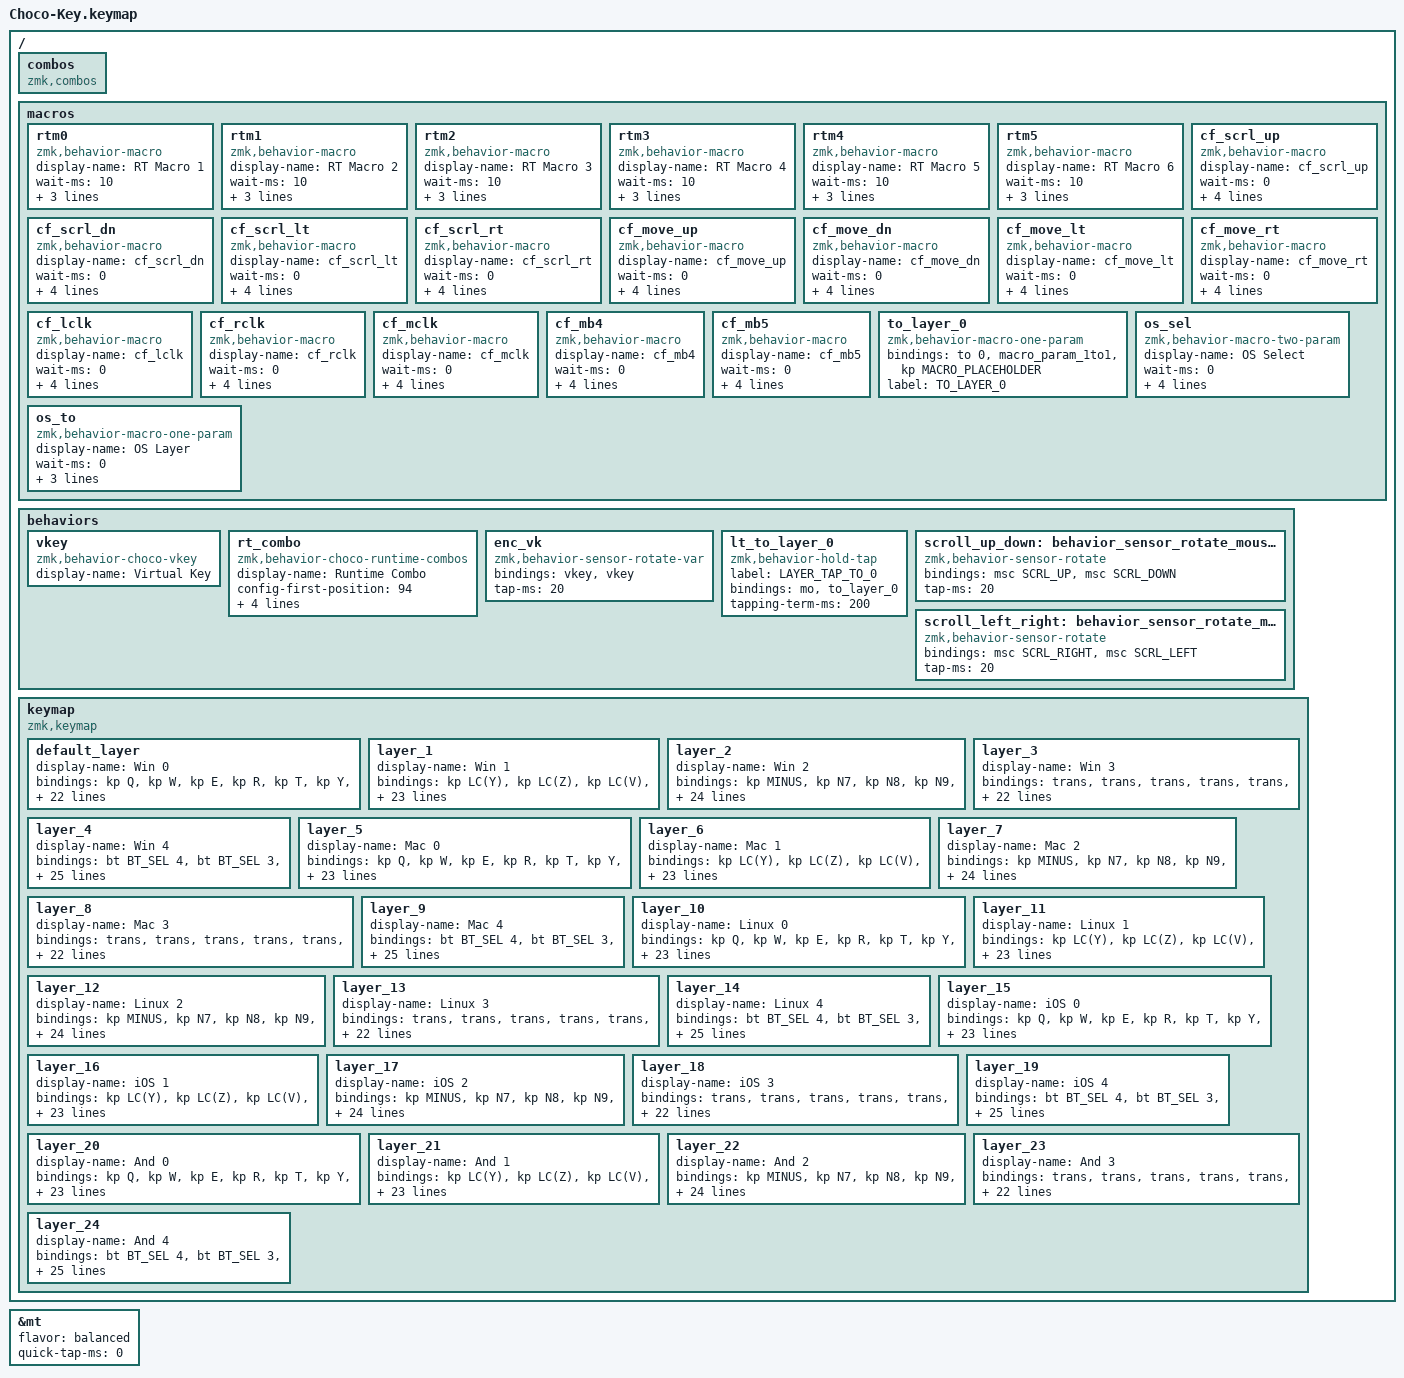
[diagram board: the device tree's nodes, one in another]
/*
 * Choco-Key キーマップ (OS 別 25 レイヤー + 即時編集 / Choco Factory で生成)
 *
 * レイヤー番号 = Bluetooth プロファイル × 5 + レイヤー番号 (プロファイルごとに OS を選べます)
 *   BT 0: 0〜4 / BT 1: 5〜9 / BT 2: 10〜14 / BT 3: 15〜19 / BT 4: 20〜24
 * 各グループの Layer 4 の右手 2 段目に OS 切替キー (&os_sel <BT プロファイル> <レイヤー>) があります。
 * 電源投入時はレイヤー 0 から始まります (ZMK はアクティブなレイヤーを保存しないため)。
 *
 * 各レイヤーのキー 1〜42 は物理キー、43〜126 は物理キーの無い仮想キーです (ZMK Studio で即時に変更できます)。
 *   43〜46: エンコーダー (右 時計回り / 右 反時計回り / 左 時計回り / 左 反時計回り)。レイヤーごとに設定可
 *   47〜94: マクロ &rtm0〜&rtm5 の中身 (8 ステップずつ)。レイヤー 0 で設定し、他のレイヤーは &trans
 *   95〜110: コンボの設定 (&rt_combo)、111〜126: コンボの動作。レイヤー 0 で設定し、他のレイヤーは &trans
 */

#include <behaviors.dtsi>
#include <dt-bindings/zmk/bt.h>
#include <dt-bindings/zmk/keys.h>
#include <dt-bindings/zmk/pointing.h>
#include <behaviors/rgbled_widget.dtsi>

#define ZMK_POINTING_DEFAULT_SCRL_VAL 100

&mt {
    flavor = "balanced";
    quick-tap-ms = <0>;
};

/ {
    combos { compatible = "zmk,combos"; };

    macros {
        // ---- Choco Factory 即時編集マクロ: 中身 (仮想キー 46〜93) は ZMK Studio で変更 ----
        rtm0: rtm0 {
            compatible = "zmk,behavior-macro";
            #binding-cells = <0>;
            display-name = "RT Macro 1";
            wait-ms = <10>;
            tap-ms = <10>;
            bindings = <&vkey 46 &vkey 47 &vkey 48 &vkey 49 &vkey 50 &vkey 51 &vkey 52 &vkey 53>;
        };

        rtm1: rtm1 {
            compatible = "zmk,behavior-macro";
            #binding-cells = <0>;
            display-name = "RT Macro 2";
            wait-ms = <10>;
            tap-ms = <10>;
            bindings = <&vkey 54 &vkey 55 &vkey 56 &vkey 57 &vkey 58 &vkey 59 &vkey 60 &vkey 61>;
        };

        rtm2: rtm2 {
            compatible = "zmk,behavior-macro";
            #binding-cells = <0>;
            display-name = "RT Macro 3";
            wait-ms = <10>;
            tap-ms = <10>;
            bindings = <&vkey 62 &vkey 63 &vkey 64 &vkey 65 &vkey 66 &vkey 67 &vkey 68 &vkey 69>;
        };

        rtm3: rtm3 {
            compatible = "zmk,behavior-macro";
            #binding-cells = <0>;
            display-name = "RT Macro 4";
            wait-ms = <10>;
            tap-ms = <10>;
            bindings = <&vkey 70 &vkey 71 &vkey 72 &vkey 73 &vkey 74 &vkey 75 &vkey 76 &vkey 77>;
        };

        rtm4: rtm4 {
            compatible = "zmk,behavior-macro";
            #binding-cells = <0>;
            display-name = "RT Macro 5";
            wait-ms = <10>;
            tap-ms = <10>;
            bindings = <&vkey 78 &vkey 79 &vkey 80 &vkey 81 &vkey 82 &vkey 83 &vkey 84 &vkey 85>;
        };

        rtm5: rtm5 {
            compatible = "zmk,behavior-macro";
            #binding-cells = <0>;
            display-name = "RT Macro 6";
            wait-ms = <10>;
            tap-ms = <10>;
            bindings = <&vkey 86 &vkey 87 &vkey 88 &vkey 89 &vkey 90 &vkey 91 &vkey 92 &vkey 93>;
        };

        // ---- ZMK Studio から書き込めない &msc / &mmv / &mkp の代わり (ZMK v0.2.1 はこれらのパラメータを検証できないため) ----
        cf_scrl_up: cf_scrl_up {
            compatible = "zmk,behavior-macro";
            #binding-cells = <0>;
            display-name = "cf_scrl_up";
            wait-ms = <0>;
            tap-ms = <0>;
            // 上スクロール: 押している間 &msc SCRL_UP を押し続ける (ZMK Studio から書き込めるようにするため)
            bindings = <&macro_press &msc SCRL_UP>, <&macro_pause_for_release>, <&macro_release &msc SCRL_UP>;
        };

        cf_scrl_dn: cf_scrl_dn {
            compatible = "zmk,behavior-macro";
            #binding-cells = <0>;
            display-name = "cf_scrl_dn";
            wait-ms = <0>;
            tap-ms = <0>;
            // 下スクロール: 押している間 &msc SCRL_DOWN を押し続ける (ZMK Studio から書き込めるようにするため)
            bindings = <&macro_press &msc SCRL_DOWN>, <&macro_pause_for_release>, <&macro_release &msc SCRL_DOWN>;
        };

        cf_scrl_lt: cf_scrl_lt {
            compatible = "zmk,behavior-macro";
            #binding-cells = <0>;
            display-name = "cf_scrl_lt";
            wait-ms = <0>;
            tap-ms = <0>;
            // 左スクロール: 押している間 &msc SCRL_LEFT を押し続ける (ZMK Studio から書き込めるようにするため)
            bindings = <&macro_press &msc SCRL_LEFT>, <&macro_pause_for_release>, <&macro_release &msc SCRL_LEFT>;
        };

        cf_scrl_rt: cf_scrl_rt {
            compatible = "zmk,behavior-macro";
            #binding-cells = <0>;
            display-name = "cf_scrl_rt";
            wait-ms = <0>;
            tap-ms = <0>;
            // 右スクロール: 押している間 &msc SCRL_RIGHT を押し続ける (ZMK Studio から書き込めるようにするため)
            bindings = <&macro_press &msc SCRL_RIGHT>, <&macro_pause_for_release>, <&macro_release &msc SCRL_RIGHT>;
        };

        cf_move_up: cf_move_up {
            compatible = "zmk,behavior-macro";
            #binding-cells = <0>;
            display-name = "cf_move_up";
            wait-ms = <0>;
            tap-ms = <0>;
            // 上へ移動: 押している間 &mmv MOVE_UP を押し続ける (ZMK Studio から書き込めるようにするため)
            bindings = <&macro_press &mmv MOVE_UP>, <&macro_pause_for_release>, <&macro_release &mmv MOVE_UP>;
        };

        cf_move_dn: cf_move_dn {
            compatible = "zmk,behavior-macro";
            #binding-cells = <0>;
            display-name = "cf_move_dn";
            wait-ms = <0>;
            tap-ms = <0>;
            // 下へ移動: 押している間 &mmv MOVE_DOWN を押し続ける (ZMK Studio から書き込めるようにするため)
            bindings = <&macro_press &mmv MOVE_DOWN>, <&macro_pause_for_release>, <&macro_release &mmv MOVE_DOWN>;
        };

        cf_move_lt: cf_move_lt {
            compatible = "zmk,behavior-macro";
            #binding-cells = <0>;
            display-name = "cf_move_lt";
            wait-ms = <0>;
            tap-ms = <0>;
            // 左へ移動: 押している間 &mmv MOVE_LEFT を押し続ける (ZMK Studio から書き込めるようにするため)
            bindings = <&macro_press &mmv MOVE_LEFT>, <&macro_pause_for_release>, <&macro_release &mmv MOVE_LEFT>;
        };

        cf_move_rt: cf_move_rt {
            compatible = "zmk,behavior-macro";
            #binding-cells = <0>;
            display-name = "cf_move_rt";
            wait-ms = <0>;
            tap-ms = <0>;
            // 右へ移動: 押している間 &mmv MOVE_RIGHT を押し続ける (ZMK Studio から書き込めるようにするため)
            bindings = <&macro_press &mmv MOVE_RIGHT>, <&macro_pause_for_release>, <&macro_release &mmv MOVE_RIGHT>;
        };

        cf_lclk: cf_lclk {
            compatible = "zmk,behavior-macro";
            #binding-cells = <0>;
            display-name = "cf_lclk";
            wait-ms = <0>;
            tap-ms = <0>;
            // 左クリック: 押している間 &mkp LCLK を押し続ける (ZMK Studio から書き込めるようにするため)
            bindings = <&macro_press &mkp LCLK>, <&macro_pause_for_release>, <&macro_release &mkp LCLK>;
        };

        cf_rclk: cf_rclk {
            compatible = "zmk,behavior-macro";
            #binding-cells = <0>;
            display-name = "cf_rclk";
            wait-ms = <0>;
            tap-ms = <0>;
            // 右クリック: 押している間 &mkp RCLK を押し続ける (ZMK Studio から書き込めるようにするため)
            bindings = <&macro_press &mkp RCLK>, <&macro_pause_for_release>, <&macro_release &mkp RCLK>;
        };

        cf_mclk: cf_mclk {
            compatible = "zmk,behavior-macro";
            #binding-cells = <0>;
            display-name = "cf_mclk";
            wait-ms = <0>;
            tap-ms = <0>;
            // 中クリック: 押している間 &mkp MCLK を押し続ける (ZMK Studio から書き込めるようにするため)
            bindings = <&macro_press &mkp MCLK>, <&macro_pause_for_release>, <&macro_release &mkp MCLK>;
        };

        cf_mb4: cf_mb4 {
            compatible = "zmk,behavior-macro";
            #binding-cells = <0>;
            display-name = "cf_mb4";
            wait-ms = <0>;
            tap-ms = <0>;
            // 戻る (ボタン4): 押している間 &mkp MB4 を押し続ける (ZMK Studio から書き込めるようにするため)
            bindings = <&macro_press &mkp MB4>, <&macro_pause_for_release>, <&macro_release &mkp MB4>;
        };

        cf_mb5: cf_mb5 {
            compatible = "zmk,behavior-macro";
            #binding-cells = <0>;
            display-name = "cf_mb5";
            wait-ms = <0>;
            tap-ms = <0>;
            // 進む (ボタン5): 押している間 &mkp MB5 を押し続ける (ZMK Studio から書き込めるようにするため)
            bindings = <&macro_press &mkp MB5>, <&macro_pause_for_release>, <&macro_release &mkp MB5>;
        };

        to_layer_0: to_layer_0 {
            compatible = "zmk,behavior-macro-one-param";
            #binding-cells = <1>;
            bindings = <&to 0 &macro_param_1to1 &kp MACRO_PLACEHOLDER>;
            label = "TO_LAYER_0";
        };

        os_sel: os_sel {
            compatible = "zmk,behavior-macro-two-param";
            #binding-cells = <2>;
            display-name = "OS Select";
            wait-ms = <0>;
            tap-ms = <10>;
            // 1 番目のパラメータ = Bluetooth プロファイル、2 番目 = 移動先のレイヤー (&bt の 3 = BT_SEL)
            bindings = <&macro_param_1to2 &bt 3 MACRO_PLACEHOLDER &macro_param_2to1 &to MACRO_PLACEHOLDER>;
        };

        os_to: os_to {
            compatible = "zmk,behavior-macro-one-param";
            #binding-cells = <1>;
            display-name = "OS Layer";
            wait-ms = <0>;
            tap-ms = <10>;
            bindings = <&macro_param_1to1 &to MACRO_PLACEHOLDER>;
        };
    };

    behaviors {
        // ---- Choco Factory 即時編集 (firmware/choco-key/studio/src) ----
        vkey: vkey {
            compatible = "zmk,behavior-choco-vkey";
            #binding-cells = <1>;
            display-name = "Virtual Key";
        };

        rt_combo: rt_combo {
            compatible = "zmk,behavior-choco-runtime-combos";
            #binding-cells = <2>;
            display-name = "Runtime Combo";
            config-first-position = <94>;
            output-first-position = <110>;
            slots = <16>;
            physical-keys = <42>;
            layers-per-group = <5>;
        };

        // エンコーダー: 回すと仮想キー (右 42/43・左 44/45) の割り当てを押す
        enc_vk: enc_vk {
            compatible = "zmk,behavior-sensor-rotate-var";
            #sensor-binding-cells = <2>;
            bindings = <&vkey>, <&vkey>;
            tap-ms = <20>;
        };

        lt_to_layer_0: lt_to_layer_0 {
            compatible = "zmk,behavior-hold-tap";
            label = "LAYER_TAP_TO_0";
            bindings = <&mo>, <&to_layer_0>;

            #binding-cells = <2>;
            tapping-term-ms = <200>;
        };

        scroll_up_down: behavior_sensor_rotate_mouse_wheel_up_down {
            compatible = "zmk,behavior-sensor-rotate";
            #sensor-binding-cells = <0>;
            bindings = <&msc SCRL_UP>, <&msc SCRL_DOWN>;

            tap-ms = <20>;
        };

        scroll_left_right: behavior_sensor_rotate_mouse_wheel_left_right {
            compatible = "zmk,behavior-sensor-rotate";
            #sensor-binding-cells = <0>;
            bindings = <&msc SCRL_RIGHT>, <&msc SCRL_LEFT>;

            tap-ms = <20>;
        };  
    };

    keymap {
        compatible = "zmk,keymap";

        default_layer {
            display-name = "Win 0";
            bindings = <
&kp Q      &kp W           &kp E     &kp R      &kp T                                        &kp Y     &kp U    &kp I           &kp O    &kp P
&kp A      &kp S           &kp D     &kp F      &kp G                                        &kp H     &kp J    &kp K           &kp L    &kp MINUS
&kp Z      &kp X           &kp C     &kp V      &kp B                                        &kp N     &kp M    &kp COMMA       &kp DOT  &kp SLASH
&kp LCTRL  &mt PSCRN LWIN  &kp LALT  &kp LSHFT  &lt 1 LA(GRAVE)  &lt 2 SPACE    &lt 3 ENTER  &kp BSPC  &kp DEL  &mt PSCRN CAPS  &kp TAB  &lt 4 ESC
&msc SCRL_UP  &msc SCRL_DOWN  &msc SCRL_RIGHT  &msc SCRL_LEFT
&none         &none           &none            &none           &none  &none  &none  &none
&none         &none           &none            &none           &none  &none  &none  &none
&none         &none           &none            &none           &none  &none  &none  &none
&none         &none           &none            &none           &none  &none  &none  &none
&none         &none           &none            &none           &none  &none  &none  &none
&none         &none           &none            &none           &none  &none  &none  &none
&none         &none           &none            &none           &none  &none  &none  &none  &none  &none  &none  &none  &none  &none  &none  &none
&none         &none           &none            &none           &none  &none  &none  &none  &none  &none  &none  &none  &none  &none  &none  &none
            >;

            sensor-bindings = <&enc_vk 42 43>, <&enc_vk 44 45>;
        };

        layer_1 {
            display-name = "Win 1";
            bindings = <
&kp LC(Y)  &kp LC(Z)  &kp LC(V)  &kp LC(C)  &kp LC(LS(C))                    &trans  &trans  &trans  &trans  &trans
&trans     &trans     &kp UP     &trans     &kp LC(S)                        &trans  &trans  &trans  &trans  &trans
&trans     &kp LEFT   &kp DOWN   &kp RIGHT  &trans                           &trans  &trans  &trans  &trans  &trans
&trans     &trans     &trans     &trans     &trans         &trans    &trans  &trans  &trans  &trans  &trans  &trans
&msc SCRL_UP  &msc SCRL_DOWN  &msc SCRL_RIGHT  &msc SCRL_LEFT
&trans        &trans          &trans           &trans          &trans  &trans  &trans  &trans
&trans        &trans          &trans           &trans          &trans  &trans  &trans  &trans
&trans        &trans          &trans           &trans          &trans  &trans  &trans  &trans
&trans        &trans          &trans           &trans          &trans  &trans  &trans  &trans
&trans        &trans          &trans           &trans          &trans  &trans  &trans  &trans
&trans        &trans          &trans           &trans          &trans  &trans  &trans  &trans
&trans        &trans          &trans           &trans          &trans  &trans  &trans  &trans  &trans  &trans  &trans  &trans  &trans  &trans  &trans  &trans
&trans        &trans          &trans           &trans          &trans  &trans  &trans  &trans  &trans  &trans  &trans  &trans  &trans  &trans  &trans  &trans
            >;

            sensor-bindings = <&enc_vk 42 43>, <&enc_vk 44 45>;
        };

        layer_2 {
            display-name = "Win 2";
            bindings = <
&kp MINUS  &kp N7  &kp N8  &kp N9  &kp PLUS                     &kp LPAR  &kp RPAR  &kp EXCL  &kp AT     &kp HASH
&kp SLASH  &kp N4  &kp N5  &kp N6  &kp ASTRK                    &kp LBKT  &kp RBKT  &kp DLLR  &kp PRCNT  &kp CARET
&kp N0     &kp N1  &kp N2  &kp N3  &kp EQUAL                    &kp LT    &kp GT    &kp AMPS  &kp SEMI   &kp SQT
&kp CARET  &trans  &trans  &trans  &trans     &trans    &trans  &trans    &trans    &trans    &trans     &trans
&msc SCRL_UP  &msc SCRL_DOWN  &msc SCRL_RIGHT  &msc SCRL_LEFT
&trans        &trans          &trans           &trans          &trans  &trans  &trans  &trans
&trans        &trans          &trans           &trans          &trans  &trans  &trans  &trans
&trans        &trans          &trans           &trans          &trans  &trans  &trans  &trans
&trans        &trans          &trans           &trans          &trans  &trans  &trans  &trans
&trans        &trans          &trans           &trans          &trans  &trans  &trans  &trans
&trans        &trans          &trans           &trans          &trans  &trans  &trans  &trans
&trans        &trans          &trans           &trans          &trans  &trans  &trans  &trans  &trans  &trans  &trans  &trans  &trans  &trans  &trans  &trans
&trans        &trans          &trans           &trans          &trans  &trans  &trans  &trans  &trans  &trans  &trans  &trans  &trans  &trans  &trans  &trans
            >;

            sensor-bindings = <&enc_vk 42 43>, <&enc_vk 44 45>;
        };

        layer_3 {
            display-name = "Win 3";
            bindings = <
&trans  &trans  &trans  &trans  &trans                    &kp F1   &kp F2   &kp F3  &kp F4  &kp F5
&trans  &trans  &trans  &trans  &trans                    &kp F6   &kp F7   &kp F8  &kp F9  &kp F10
&trans  &trans  &trans  &trans  &trans                    &kp F11  &kp F12  &trans  &trans  &trans
&trans  &trans  &trans  &trans  &trans  &trans    &trans  &trans   &trans   &trans  &trans  &trans
&msc SCRL_UP  &msc SCRL_DOWN  &msc SCRL_RIGHT  &msc SCRL_LEFT
&trans        &trans          &trans           &trans          &trans  &trans  &trans  &trans
&trans        &trans          &trans           &trans          &trans  &trans  &trans  &trans
&trans        &trans          &trans           &trans          &trans  &trans  &trans  &trans
&trans        &trans          &trans           &trans          &trans  &trans  &trans  &trans
&trans        &trans          &trans           &trans          &trans  &trans  &trans  &trans
&trans        &trans          &trans           &trans          &trans  &trans  &trans  &trans
&trans        &trans          &trans           &trans          &trans  &trans  &trans  &trans  &trans  &trans  &trans  &trans  &trans  &trans  &trans  &trans
&trans        &trans          &trans           &trans          &trans  &trans  &trans  &trans  &trans  &trans  &trans  &trans  &trans  &trans  &trans  &trans
            >;

            sensor-bindings = <&enc_vk 42 43>, <&enc_vk 44 45>;
        };

        layer_4 {
            display-name = "Win 4";
            bindings = <
&bt BT_SEL 4    &bt BT_SEL 3  &bt BT_SEL 2  &bt BT_SEL 1  &bt BT_SEL 0                         &studio_unlock  &trans       &trans        &trans        &trans
&bt BT_CLR_ALL  &trans        &trans        &trans        &ind_bat                             &os_sel 0 0     &os_sel 1 5  &os_sel 2 10  &os_sel 3 15  &os_sel 4 20
&bt BT_CLR      &trans        &trans        &trans        &trans                               &trans          &trans       &trans        &trans        &trans
&trans          &trans        &trans        &trans        &trans        &bootloader    &trans  &trans          &trans       &trans        &trans        &trans
&msc SCRL_UP  &msc SCRL_DOWN  &msc SCRL_RIGHT  &msc SCRL_LEFT
&trans        &trans          &trans           &trans          &trans  &trans  &trans  &trans
&trans        &trans          &trans           &trans          &trans  &trans  &trans  &trans
&trans        &trans          &trans           &trans          &trans  &trans  &trans  &trans
&trans        &trans          &trans           &trans          &trans  &trans  &trans  &trans
&trans        &trans          &trans           &trans          &trans  &trans  &trans  &trans
&trans        &trans          &trans           &trans          &trans  &trans  &trans  &trans
&trans        &trans          &trans           &trans          &trans  &trans  &trans  &trans  &trans  &trans  &trans  &trans  &trans  &trans  &trans  &trans
&trans        &trans          &trans           &trans          &trans  &trans  &trans  &trans  &trans  &trans  &trans  &trans  &trans  &trans  &trans  &trans
            >;

            sensor-bindings = <&enc_vk 42 43>, <&enc_vk 44 45>;
        };

        layer_5 {
            display-name = "Mac 0";
            bindings = <
&kp Q      &kp W           &kp E     &kp R      &kp T                                        &kp Y     &kp U    &kp I           &kp O    &kp P
&kp A      &kp S           &kp D     &kp F      &kp G                                        &kp H     &kp J    &kp K           &kp L    &kp MINUS
&kp Z      &kp X           &kp C     &kp V      &kp B                                        &kp N     &kp M    &kp COMMA       &kp DOT  &kp SLASH
&kp LCTRL  &mt PSCRN LGUI  &kp LALT  &kp LSHFT  &lt 6 LA(GRAVE)  &lt 7 SPACE    &lt 8 ENTER  &kp BSPC  &kp DEL  &mt PSCRN CAPS  &kp TAB  &lt 9 ESC
&msc SCRL_UP  &msc SCRL_DOWN  &msc SCRL_RIGHT  &msc SCRL_LEFT
&trans        &trans          &trans           &trans          &trans  &trans  &trans  &trans
&trans        &trans          &trans           &trans          &trans  &trans  &trans  &trans
&trans        &trans          &trans           &trans          &trans  &trans  &trans  &trans
&trans        &trans          &trans           &trans          &trans  &trans  &trans  &trans
&trans        &trans          &trans           &trans          &trans  &trans  &trans  &trans
&trans        &trans          &trans           &trans          &trans  &trans  &trans  &trans
&trans        &trans          &trans           &trans          &trans  &trans  &trans  &trans  &trans  &trans  &trans  &trans  &trans  &trans  &trans  &trans
&trans        &trans          &trans           &trans          &trans  &trans  &trans  &trans  &trans  &trans  &trans  &trans  &trans  &trans  &trans  &trans
            >;

            sensor-bindings = <&enc_vk 42 43>, <&enc_vk 44 45>;
        };

        layer_6 {
            display-name = "Mac 1";
            bindings = <
&kp LC(Y)  &kp LC(Z)  &kp LC(V)  &kp LC(C)  &kp LC(LS(C))                    &trans  &trans  &trans  &trans  &trans
&trans     &trans     &kp UP     &trans     &kp LC(S)                        &trans  &trans  &trans  &trans  &trans
&trans     &kp LEFT   &kp DOWN   &kp RIGHT  &trans                           &trans  &trans  &trans  &trans  &trans
&trans     &trans     &trans     &trans     &trans         &trans    &trans  &trans  &trans  &trans  &trans  &trans
&msc SCRL_UP  &msc SCRL_DOWN  &msc SCRL_RIGHT  &msc SCRL_LEFT
&trans        &trans          &trans           &trans          &trans  &trans  &trans  &trans
&trans        &trans          &trans           &trans          &trans  &trans  &trans  &trans
&trans        &trans          &trans           &trans          &trans  &trans  &trans  &trans
&trans        &trans          &trans           &trans          &trans  &trans  &trans  &trans
&trans        &trans          &trans           &trans          &trans  &trans  &trans  &trans
&trans        &trans          &trans           &trans          &trans  &trans  &trans  &trans
&trans        &trans          &trans           &trans          &trans  &trans  &trans  &trans  &trans  &trans  &trans  &trans  &trans  &trans  &trans  &trans
&trans        &trans          &trans           &trans          &trans  &trans  &trans  &trans  &trans  &trans  &trans  &trans  &trans  &trans  &trans  &trans
            >;

            sensor-bindings = <&enc_vk 42 43>, <&enc_vk 44 45>;
        };

        layer_7 {
            display-name = "Mac 2";
            bindings = <
&kp MINUS  &kp N7  &kp N8  &kp N9  &kp PLUS                     &kp LPAR  &kp RPAR  &kp EXCL  &kp AT     &kp HASH
&kp SLASH  &kp N4  &kp N5  &kp N6  &kp ASTRK                    &kp LBKT  &kp RBKT  &kp DLLR  &kp PRCNT  &kp CARET
&kp N0     &kp N1  &kp N2  &kp N3  &kp EQUAL                    &kp LT    &kp GT    &kp AMPS  &kp SEMI   &kp SQT
&kp CARET  &trans  &trans  &trans  &trans     &trans    &trans  &trans    &trans    &trans    &trans     &trans
&msc SCRL_UP  &msc SCRL_DOWN  &msc SCRL_RIGHT  &msc SCRL_LEFT
&trans        &trans          &trans           &trans          &trans  &trans  &trans  &trans
&trans        &trans          &trans           &trans          &trans  &trans  &trans  &trans
&trans        &trans          &trans           &trans          &trans  &trans  &trans  &trans
&trans        &trans          &trans           &trans          &trans  &trans  &trans  &trans
&trans        &trans          &trans           &trans          &trans  &trans  &trans  &trans
&trans        &trans          &trans           &trans          &trans  &trans  &trans  &trans
&trans        &trans          &trans           &trans          &trans  &trans  &trans  &trans  &trans  &trans  &trans  &trans  &trans  &trans  &trans  &trans
&trans        &trans          &trans           &trans          &trans  &trans  &trans  &trans  &trans  &trans  &trans  &trans  &trans  &trans  &trans  &trans
            >;

            sensor-bindings = <&enc_vk 42 43>, <&enc_vk 44 45>;
        };

        layer_8 {
            display-name = "Mac 3";
            bindings = <
&trans  &trans  &trans  &trans  &trans                    &kp F1   &kp F2   &kp F3  &kp F4  &kp F5
&trans  &trans  &trans  &trans  &trans                    &kp F6   &kp F7   &kp F8  &kp F9  &kp F10
&trans  &trans  &trans  &trans  &trans                    &kp F11  &kp F12  &trans  &trans  &trans
&trans  &trans  &trans  &trans  &trans  &trans    &trans  &trans   &trans   &trans  &trans  &trans
&msc SCRL_UP  &msc SCRL_DOWN  &msc SCRL_RIGHT  &msc SCRL_LEFT
&trans        &trans          &trans           &trans          &trans  &trans  &trans  &trans
&trans        &trans          &trans           &trans          &trans  &trans  &trans  &trans
&trans        &trans          &trans           &trans          &trans  &trans  &trans  &trans
&trans        &trans          &trans           &trans          &trans  &trans  &trans  &trans
&trans        &trans          &trans           &trans          &trans  &trans  &trans  &trans
&trans        &trans          &trans           &trans          &trans  &trans  &trans  &trans
&trans        &trans          &trans           &trans          &trans  &trans  &trans  &trans  &trans  &trans  &trans  &trans  &trans  &trans  &trans  &trans
&trans        &trans          &trans           &trans          &trans  &trans  &trans  &trans  &trans  &trans  &trans  &trans  &trans  &trans  &trans  &trans
            >;

            sensor-bindings = <&enc_vk 42 43>, <&enc_vk 44 45>;
        };

        layer_9 {
            display-name = "Mac 4";
            bindings = <
&bt BT_SEL 4    &bt BT_SEL 3  &bt BT_SEL 2  &bt BT_SEL 1  &bt BT_SEL 0                         &studio_unlock  &trans       &trans        &trans        &trans
&bt BT_CLR_ALL  &trans        &trans        &trans        &ind_bat                             &os_sel 0 0     &os_sel 1 5  &os_sel 2 10  &os_sel 3 15  &os_sel 4 20
&bt BT_CLR      &trans        &trans        &trans        &trans                               &trans          &trans       &trans        &trans        &trans
&trans          &trans        &trans        &trans        &trans        &bootloader    &trans  &trans          &trans       &trans        &trans        &trans
&msc SCRL_UP  &msc SCRL_DOWN  &msc SCRL_RIGHT  &msc SCRL_LEFT
&trans        &trans          &trans           &trans          &trans  &trans  &trans  &trans
&trans        &trans          &trans           &trans          &trans  &trans  &trans  &trans
&trans        &trans          &trans           &trans          &trans  &trans  &trans  &trans
&trans        &trans          &trans           &trans          &trans  &trans  &trans  &trans
&trans        &trans          &trans           &trans          &trans  &trans  &trans  &trans
&trans        &trans          &trans           &trans          &trans  &trans  &trans  &trans
&trans        &trans          &trans           &trans          &trans  &trans  &trans  &trans  &trans  &trans  &trans  &trans  &trans  &trans  &trans  &trans
&trans        &trans          &trans           &trans          &trans  &trans  &trans  &trans  &trans  &trans  &trans  &trans  &trans  &trans  &trans  &trans
            >;

            sensor-bindings = <&enc_vk 42 43>, <&enc_vk 44 45>;
        };

        layer_10 {
            display-name = "Linux 0";
            bindings = <
&kp Q      &kp W           &kp E     &kp R      &kp T                                           &kp Y     &kp U    &kp I           &kp O    &kp P
&kp A      &kp S           &kp D     &kp F      &kp G                                           &kp H     &kp J    &kp K           &kp L    &kp MINUS
&kp Z      &kp X           &kp C     &kp V      &kp B                                           &kp N     &kp M    &kp COMMA       &kp DOT  &kp SLASH
&kp LCTRL  &mt PSCRN LGUI  &kp LALT  &kp LSHFT  &lt 11 LA(GRAVE)  &lt 12 SPACE    &lt 13 ENTER  &kp BSPC  &kp DEL  &mt PSCRN CAPS  &kp TAB  &lt 14 ESC
&msc SCRL_UP  &msc SCRL_DOWN  &msc SCRL_RIGHT  &msc SCRL_LEFT
&trans        &trans          &trans           &trans          &trans  &trans  &trans  &trans
&trans        &trans          &trans           &trans          &trans  &trans  &trans  &trans
&trans        &trans          &trans           &trans          &trans  &trans  &trans  &trans
&trans        &trans          &trans           &trans          &trans  &trans  &trans  &trans
&trans        &trans          &trans           &trans          &trans  &trans  &trans  &trans
&trans        &trans          &trans           &trans          &trans  &trans  &trans  &trans
&trans        &trans          &trans           &trans          &trans  &trans  &trans  &trans  &trans  &trans  &trans  &trans  &trans  &trans  &trans  &trans
&trans        &trans          &trans           &trans          &trans  &trans  &trans  &trans  &trans  &trans  &trans  &trans  &trans  &trans  &trans  &trans
            >;

            sensor-bindings = <&enc_vk 42 43>, <&enc_vk 44 45>;
        };

        layer_11 {
            display-name = "Linux 1";
            bindings = <
&kp LC(Y)  &kp LC(Z)  &kp LC(V)  &kp LC(C)  &kp LC(LS(C))                    &trans  &trans  &trans  &trans  &trans
&trans     &trans     &kp UP     &trans     &kp LC(S)                        &trans  &trans  &trans  &trans  &trans
&trans     &kp LEFT   &kp DOWN   &kp RIGHT  &trans                           &trans  &trans  &trans  &trans  &trans
&trans     &trans     &trans     &trans     &trans         &trans    &trans  &trans  &trans  &trans  &trans  &trans
&msc SCRL_UP  &msc SCRL_DOWN  &msc SCRL_RIGHT  &msc SCRL_LEFT
&trans        &trans          &trans           &trans          &trans  &trans  &trans  &trans
&trans        &trans          &trans           &trans          &trans  &trans  &trans  &trans
&trans        &trans          &trans           &trans          &trans  &trans  &trans  &trans
&trans        &trans          &trans           &trans          &trans  &trans  &trans  &trans
&trans        &trans          &trans           &trans          &trans  &trans  &trans  &trans
&trans        &trans          &trans           &trans          &trans  &trans  &trans  &trans
&trans        &trans          &trans           &trans          &trans  &trans  &trans  &trans  &trans  &trans  &trans  &trans  &trans  &trans  &trans  &trans
&trans        &trans          &trans           &trans          &trans  &trans  &trans  &trans  &trans  &trans  &trans  &trans  &trans  &trans  &trans  &trans
            >;

            sensor-bindings = <&enc_vk 42 43>, <&enc_vk 44 45>;
        };

        layer_12 {
            display-name = "Linux 2";
            bindings = <
&kp MINUS  &kp N7  &kp N8  &kp N9  &kp PLUS                     &kp LPAR  &kp RPAR  &kp EXCL  &kp AT     &kp HASH
&kp SLASH  &kp N4  &kp N5  &kp N6  &kp ASTRK                    &kp LBKT  &kp RBKT  &kp DLLR  &kp PRCNT  &kp CARET
&kp N0     &kp N1  &kp N2  &kp N3  &kp EQUAL                    &kp LT    &kp GT    &kp AMPS  &kp SEMI   &kp SQT
&kp CARET  &trans  &trans  &trans  &trans     &trans    &trans  &trans    &trans    &trans    &trans     &trans
&msc SCRL_UP  &msc SCRL_DOWN  &msc SCRL_RIGHT  &msc SCRL_LEFT
&trans        &trans          &trans           &trans          &trans  &trans  &trans  &trans
&trans        &trans          &trans           &trans          &trans  &trans  &trans  &trans
&trans        &trans          &trans           &trans          &trans  &trans  &trans  &trans
&trans        &trans          &trans           &trans          &trans  &trans  &trans  &trans
&trans        &trans          &trans           &trans          &trans  &trans  &trans  &trans
&trans        &trans          &trans           &trans          &trans  &trans  &trans  &trans
&trans        &trans          &trans           &trans          &trans  &trans  &trans  &trans  &trans  &trans  &trans  &trans  &trans  &trans  &trans  &trans
&trans        &trans          &trans           &trans          &trans  &trans  &trans  &trans  &trans  &trans  &trans  &trans  &trans  &trans  &trans  &trans
            >;

            sensor-bindings = <&enc_vk 42 43>, <&enc_vk 44 45>;
        };

        layer_13 {
            display-name = "Linux 3";
            bindings = <
&trans  &trans  &trans  &trans  &trans                    &kp F1   &kp F2   &kp F3  &kp F4  &kp F5
&trans  &trans  &trans  &trans  &trans                    &kp F6   &kp F7   &kp F8  &kp F9  &kp F10
&trans  &trans  &trans  &trans  &trans                    &kp F11  &kp F12  &trans  &trans  &trans
&trans  &trans  &trans  &trans  &trans  &trans    &trans  &trans   &trans   &trans  &trans  &trans
&msc SCRL_UP  &msc SCRL_DOWN  &msc SCRL_RIGHT  &msc SCRL_LEFT
&trans        &trans          &trans           &trans          &trans  &trans  &trans  &trans
&trans        &trans          &trans           &trans          &trans  &trans  &trans  &trans
&trans        &trans          &trans           &trans          &trans  &trans  &trans  &trans
&trans        &trans          &trans           &trans          &trans  &trans  &trans  &trans
&trans        &trans          &trans           &trans          &trans  &trans  &trans  &trans
&trans        &trans          &trans           &trans          &trans  &trans  &trans  &trans
&trans        &trans          &trans           &trans          &trans  &trans  &trans  &trans  &trans  &trans  &trans  &trans  &trans  &trans  &trans  &trans
&trans        &trans          &trans           &trans          &trans  &trans  &trans  &trans  &trans  &trans  &trans  &trans  &trans  &trans  &trans  &trans
            >;

            sensor-bindings = <&enc_vk 42 43>, <&enc_vk 44 45>;
        };

        layer_14 {
            display-name = "Linux 4";
            bindings = <
&bt BT_SEL 4    &bt BT_SEL 3  &bt BT_SEL 2  &bt BT_SEL 1  &bt BT_SEL 0                         &studio_unlock  &trans       &trans        &trans        &trans
&bt BT_CLR_ALL  &trans        &trans        &trans        &ind_bat                             &os_sel 0 0     &os_sel 1 5  &os_sel 2 10  &os_sel 3 15  &os_sel 4 20
&bt BT_CLR      &trans        &trans        &trans        &trans                               &trans          &trans       &trans        &trans        &trans
&trans          &trans        &trans        &trans        &trans        &bootloader    &trans  &trans          &trans       &trans        &trans        &trans
&msc SCRL_UP  &msc SCRL_DOWN  &msc SCRL_RIGHT  &msc SCRL_LEFT
&trans        &trans          &trans           &trans          &trans  &trans  &trans  &trans
&trans        &trans          &trans           &trans          &trans  &trans  &trans  &trans
&trans        &trans          &trans           &trans          &trans  &trans  &trans  &trans
&trans        &trans          &trans           &trans          &trans  &trans  &trans  &trans
&trans        &trans          &trans           &trans          &trans  &trans  &trans  &trans
&trans        &trans          &trans           &trans          &trans  &trans  &trans  &trans
&trans        &trans          &trans           &trans          &trans  &trans  &trans  &trans  &trans  &trans  &trans  &trans  &trans  &trans  &trans  &trans
&trans        &trans          &trans           &trans          &trans  &trans  &trans  &trans  &trans  &trans  &trans  &trans  &trans  &trans  &trans  &trans
            >;

            sensor-bindings = <&enc_vk 42 43>, <&enc_vk 44 45>;
        };

        layer_15 {
            display-name = "iOS 0";
            bindings = <
&kp Q      &kp W           &kp E     &kp R      &kp T                                           &kp Y     &kp U    &kp I           &kp O    &kp P
&kp A      &kp S           &kp D     &kp F      &kp G                                           &kp H     &kp J    &kp K           &kp L    &kp MINUS
&kp Z      &kp X           &kp C     &kp V      &kp B                                           &kp N     &kp M    &kp COMMA       &kp DOT  &kp SLASH
&kp LCTRL  &mt PSCRN LGUI  &kp LALT  &kp LSHFT  &lt 16 LA(GRAVE)  &lt 17 SPACE    &lt 18 ENTER  &kp BSPC  &kp DEL  &mt PSCRN CAPS  &kp TAB  &lt 19 ESC
&msc SCRL_UP  &msc SCRL_DOWN  &msc SCRL_RIGHT  &msc SCRL_LEFT
&trans        &trans          &trans           &trans          &trans  &trans  &trans  &trans
&trans        &trans          &trans           &trans          &trans  &trans  &trans  &trans
&trans        &trans          &trans           &trans          &trans  &trans  &trans  &trans
&trans        &trans          &trans           &trans          &trans  &trans  &trans  &trans
&trans        &trans          &trans           &trans          &trans  &trans  &trans  &trans
&trans        &trans          &trans           &trans          &trans  &trans  &trans  &trans
&trans        &trans          &trans           &trans          &trans  &trans  &trans  &trans  &trans  &trans  &trans  &trans  &trans  &trans  &trans  &trans
&trans        &trans          &trans           &trans          &trans  &trans  &trans  &trans  &trans  &trans  &trans  &trans  &trans  &trans  &trans  &trans
            >;

            sensor-bindings = <&enc_vk 42 43>, <&enc_vk 44 45>;
        };

        layer_16 {
            display-name = "iOS 1";
            bindings = <
&kp LC(Y)  &kp LC(Z)  &kp LC(V)  &kp LC(C)  &kp LC(LS(C))                    &trans  &trans  &trans  &trans  &trans
&trans     &trans     &kp UP     &trans     &kp LC(S)                        &trans  &trans  &trans  &trans  &trans
&trans     &kp LEFT   &kp DOWN   &kp RIGHT  &trans                           &trans  &trans  &trans  &trans  &trans
&trans     &trans     &trans     &trans     &trans         &trans    &trans  &trans  &trans  &trans  &trans  &trans
&msc SCRL_UP  &msc SCRL_DOWN  &msc SCRL_RIGHT  &msc SCRL_LEFT
&trans        &trans          &trans           &trans          &trans  &trans  &trans  &trans
&trans        &trans          &trans           &trans          &trans  &trans  &trans  &trans
&trans        &trans          &trans           &trans          &trans  &trans  &trans  &trans
&trans        &trans          &trans           &trans          &trans  &trans  &trans  &trans
&trans        &trans          &trans           &trans          &trans  &trans  &trans  &trans
&trans        &trans          &trans           &trans          &trans  &trans  &trans  &trans
&trans        &trans          &trans           &trans          &trans  &trans  &trans  &trans  &trans  &trans  &trans  &trans  &trans  &trans  &trans  &trans
&trans        &trans          &trans           &trans          &trans  &trans  &trans  &trans  &trans  &trans  &trans  &trans  &trans  &trans  &trans  &trans
            >;

            sensor-bindings = <&enc_vk 42 43>, <&enc_vk 44 45>;
        };

        layer_17 {
            display-name = "iOS 2";
            bindings = <
&kp MINUS  &kp N7  &kp N8  &kp N9  &kp PLUS                     &kp LPAR  &kp RPAR  &kp EXCL  &kp AT     &kp HASH
&kp SLASH  &kp N4  &kp N5  &kp N6  &kp ASTRK                    &kp LBKT  &kp RBKT  &kp DLLR  &kp PRCNT  &kp CARET
&kp N0     &kp N1  &kp N2  &kp N3  &kp EQUAL                    &kp LT    &kp GT    &kp AMPS  &kp SEMI   &kp SQT
&kp CARET  &trans  &trans  &trans  &trans     &trans    &trans  &trans    &trans    &trans    &trans     &trans
&msc SCRL_UP  &msc SCRL_DOWN  &msc SCRL_RIGHT  &msc SCRL_LEFT
&trans        &trans          &trans           &trans          &trans  &trans  &trans  &trans
&trans        &trans          &trans           &trans          &trans  &trans  &trans  &trans
&trans        &trans          &trans           &trans          &trans  &trans  &trans  &trans
&trans        &trans          &trans           &trans          &trans  &trans  &trans  &trans
&trans        &trans          &trans           &trans          &trans  &trans  &trans  &trans
&trans        &trans          &trans           &trans          &trans  &trans  &trans  &trans
&trans        &trans          &trans           &trans          &trans  &trans  &trans  &trans  &trans  &trans  &trans  &trans  &trans  &trans  &trans  &trans
&trans        &trans          &trans           &trans          &trans  &trans  &trans  &trans  &trans  &trans  &trans  &trans  &trans  &trans  &trans  &trans
            >;

            sensor-bindings = <&enc_vk 42 43>, <&enc_vk 44 45>;
        };

        layer_18 {
            display-name = "iOS 3";
            bindings = <
&trans  &trans  &trans  &trans  &trans                    &kp F1   &kp F2   &kp F3  &kp F4  &kp F5
&trans  &trans  &trans  &trans  &trans                    &kp F6   &kp F7   &kp F8  &kp F9  &kp F10
&trans  &trans  &trans  &trans  &trans                    &kp F11  &kp F12  &trans  &trans  &trans
&trans  &trans  &trans  &trans  &trans  &trans    &trans  &trans   &trans   &trans  &trans  &trans
&msc SCRL_UP  &msc SCRL_DOWN  &msc SCRL_RIGHT  &msc SCRL_LEFT
&trans        &trans          &trans           &trans          &trans  &trans  &trans  &trans
&trans        &trans          &trans           &trans          &trans  &trans  &trans  &trans
&trans        &trans          &trans           &trans          &trans  &trans  &trans  &trans
&trans        &trans          &trans           &trans          &trans  &trans  &trans  &trans
&trans        &trans          &trans           &trans          &trans  &trans  &trans  &trans
&trans        &trans          &trans           &trans          &trans  &trans  &trans  &trans
&trans        &trans          &trans           &trans          &trans  &trans  &trans  &trans  &trans  &trans  &trans  &trans  &trans  &trans  &trans  &trans
&trans        &trans          &trans           &trans          &trans  &trans  &trans  &trans  &trans  &trans  &trans  &trans  &trans  &trans  &trans  &trans
            >;

            sensor-bindings = <&enc_vk 42 43>, <&enc_vk 44 45>;
        };

        layer_19 {
            display-name = "iOS 4";
            bindings = <
&bt BT_SEL 4    &bt BT_SEL 3  &bt BT_SEL 2  &bt BT_SEL 1  &bt BT_SEL 0                         &studio_unlock  &trans       &trans        &trans        &trans
&bt BT_CLR_ALL  &trans        &trans        &trans        &ind_bat                             &os_sel 0 0     &os_sel 1 5  &os_sel 2 10  &os_sel 3 15  &os_sel 4 20
&bt BT_CLR      &trans        &trans        &trans        &trans                               &trans          &trans       &trans        &trans        &trans
&trans          &trans        &trans        &trans        &trans        &bootloader    &trans  &trans          &trans       &trans        &trans        &trans
&msc SCRL_UP  &msc SCRL_DOWN  &msc SCRL_RIGHT  &msc SCRL_LEFT
&trans        &trans          &trans           &trans          &trans  &trans  &trans  &trans
&trans        &trans          &trans           &trans          &trans  &trans  &trans  &trans
&trans        &trans          &trans           &trans          &trans  &trans  &trans  &trans
&trans        &trans          &trans           &trans          &trans  &trans  &trans  &trans
&trans        &trans          &trans           &trans          &trans  &trans  &trans  &trans
&trans        &trans          &trans           &trans          &trans  &trans  &trans  &trans
&trans        &trans          &trans           &trans          &trans  &trans  &trans  &trans  &trans  &trans  &trans  &trans  &trans  &trans  &trans  &trans
&trans        &trans          &trans           &trans          &trans  &trans  &trans  &trans  &trans  &trans  &trans  &trans  &trans  &trans  &trans  &trans
            >;

            sensor-bindings = <&enc_vk 42 43>, <&enc_vk 44 45>;
        };

        layer_20 {
            display-name = "And 0";
            bindings = <
&kp Q      &kp W           &kp E     &kp R      &kp T                                           &kp Y     &kp U    &kp I           &kp O    &kp P
&kp A      &kp S           &kp D     &kp F      &kp G                                           &kp H     &kp J    &kp K           &kp L    &kp MINUS
&kp Z      &kp X           &kp C     &kp V      &kp B                                           &kp N     &kp M    &kp COMMA       &kp DOT  &kp SLASH
&kp LCTRL  &mt PSCRN LGUI  &kp LALT  &kp LSHFT  &lt 21 LA(GRAVE)  &lt 22 SPACE    &lt 23 ENTER  &kp BSPC  &kp DEL  &mt PSCRN CAPS  &kp TAB  &lt 24 ESC
&msc SCRL_UP  &msc SCRL_DOWN  &msc SCRL_RIGHT  &msc SCRL_LEFT
&trans        &trans          &trans           &trans          &trans  &trans  &trans  &trans
&trans        &trans          &trans           &trans          &trans  &trans  &trans  &trans
&trans        &trans          &trans           &trans          &trans  &trans  &trans  &trans
&trans        &trans          &trans           &trans          &trans  &trans  &trans  &trans
&trans        &trans          &trans           &trans          &trans  &trans  &trans  &trans
&trans        &trans          &trans           &trans          &trans  &trans  &trans  &trans
&trans        &trans          &trans           &trans          &trans  &trans  &trans  &trans  &trans  &trans  &trans  &trans  &trans  &trans  &trans  &trans
&trans        &trans          &trans           &trans          &trans  &trans  &trans  &trans  &trans  &trans  &trans  &trans  &trans  &trans  &trans  &trans
            >;

            sensor-bindings = <&enc_vk 42 43>, <&enc_vk 44 45>;
        };

        layer_21 {
            display-name = "And 1";
            bindings = <
&kp LC(Y)  &kp LC(Z)  &kp LC(V)  &kp LC(C)  &kp LC(LS(C))                    &trans  &trans  &trans  &trans  &trans
&trans     &trans     &kp UP     &trans     &kp LC(S)                        &trans  &trans  &trans  &trans  &trans
&trans     &kp LEFT   &kp DOWN   &kp RIGHT  &trans                           &trans  &trans  &trans  &trans  &trans
&trans     &trans     &trans     &trans     &trans         &trans    &trans  &trans  &trans  &trans  &trans  &trans
&msc SCRL_UP  &msc SCRL_DOWN  &msc SCRL_RIGHT  &msc SCRL_LEFT
&trans        &trans          &trans           &trans          &trans  &trans  &trans  &trans
&trans        &trans          &trans           &trans          &trans  &trans  &trans  &trans
&trans        &trans          &trans           &trans          &trans  &trans  &trans  &trans
&trans        &trans          &trans           &trans          &trans  &trans  &trans  &trans
&trans        &trans          &trans           &trans          &trans  &trans  &trans  &trans
&trans        &trans          &trans           &trans          &trans  &trans  &trans  &trans
&trans        &trans          &trans           &trans          &trans  &trans  &trans  &trans  &trans  &trans  &trans  &trans  &trans  &trans  &trans  &trans
&trans        &trans          &trans           &trans          &trans  &trans  &trans  &trans  &trans  &trans  &trans  &trans  &trans  &trans  &trans  &trans
            >;

            sensor-bindings = <&enc_vk 42 43>, <&enc_vk 44 45>;
        };

        layer_22 {
            display-name = "And 2";
            bindings = <
&kp MINUS  &kp N7  &kp N8  &kp N9  &kp PLUS                     &kp LPAR  &kp RPAR  &kp EXCL  &kp AT     &kp HASH
&kp SLASH  &kp N4  &kp N5  &kp N6  &kp ASTRK                    &kp LBKT  &kp RBKT  &kp DLLR  &kp PRCNT  &kp CARET
&kp N0     &kp N1  &kp N2  &kp N3  &kp EQUAL                    &kp LT    &kp GT    &kp AMPS  &kp SEMI   &kp SQT
&kp CARET  &trans  &trans  &trans  &trans     &trans    &trans  &trans    &trans    &trans    &trans     &trans
&msc SCRL_UP  &msc SCRL_DOWN  &msc SCRL_RIGHT  &msc SCRL_LEFT
&trans        &trans          &trans           &trans          &trans  &trans  &trans  &trans
&trans        &trans          &trans           &trans          &trans  &trans  &trans  &trans
&trans        &trans          &trans           &trans          &trans  &trans  &trans  &trans
&trans        &trans          &trans           &trans          &trans  &trans  &trans  &trans
&trans        &trans          &trans           &trans          &trans  &trans  &trans  &trans
&trans        &trans          &trans           &trans          &trans  &trans  &trans  &trans
&trans        &trans          &trans           &trans          &trans  &trans  &trans  &trans  &trans  &trans  &trans  &trans  &trans  &trans  &trans  &trans
&trans        &trans          &trans           &trans          &trans  &trans  &trans  &trans  &trans  &trans  &trans  &trans  &trans  &trans  &trans  &trans
            >;

            sensor-bindings = <&enc_vk 42 43>, <&enc_vk 44 45>;
        };

        layer_23 {
            display-name = "And 3";
            bindings = <
&trans  &trans  &trans  &trans  &trans                    &kp F1   &kp F2   &kp F3  &kp F4  &kp F5
&trans  &trans  &trans  &trans  &trans                    &kp F6   &kp F7   &kp F8  &kp F9  &kp F10
&trans  &trans  &trans  &trans  &trans                    &kp F11  &kp F12  &trans  &trans  &trans
&trans  &trans  &trans  &trans  &trans  &trans    &trans  &trans   &trans   &trans  &trans  &trans
&msc SCRL_UP  &msc SCRL_DOWN  &msc SCRL_RIGHT  &msc SCRL_LEFT
&trans        &trans          &trans           &trans          &trans  &trans  &trans  &trans
&trans        &trans          &trans           &trans          &trans  &trans  &trans  &trans
&trans        &trans          &trans           &trans          &trans  &trans  &trans  &trans
&trans        &trans          &trans           &trans          &trans  &trans  &trans  &trans
&trans        &trans          &trans           &trans          &trans  &trans  &trans  &trans
&trans        &trans          &trans           &trans          &trans  &trans  &trans  &trans
&trans        &trans          &trans           &trans          &trans  &trans  &trans  &trans  &trans  &trans  &trans  &trans  &trans  &trans  &trans  &trans
&trans        &trans          &trans           &trans          &trans  &trans  &trans  &trans  &trans  &trans  &trans  &trans  &trans  &trans  &trans  &trans
            >;

            sensor-bindings = <&enc_vk 42 43>, <&enc_vk 44 45>;
        };

        layer_24 {
            display-name = "And 4";
            bindings = <
&bt BT_SEL 4    &bt BT_SEL 3  &bt BT_SEL 2  &bt BT_SEL 1  &bt BT_SEL 0                         &studio_unlock  &trans       &trans        &trans        &trans
&bt BT_CLR_ALL  &trans        &trans        &trans        &ind_bat                             &os_sel 0 0     &os_sel 1 5  &os_sel 2 10  &os_sel 3 15  &os_sel 4 20
&bt BT_CLR      &trans        &trans        &trans        &trans                               &trans          &trans       &trans        &trans        &trans
&trans          &trans        &trans        &trans        &trans        &bootloader    &trans  &trans          &trans       &trans        &trans        &trans
&msc SCRL_UP  &msc SCRL_DOWN  &msc SCRL_RIGHT  &msc SCRL_LEFT
&trans        &trans          &trans           &trans          &trans  &trans  &trans  &trans
&trans        &trans          &trans           &trans          &trans  &trans  &trans  &trans
&trans        &trans          &trans           &trans          &trans  &trans  &trans  &trans
&trans        &trans          &trans           &trans          &trans  &trans  &trans  &trans
&trans        &trans          &trans           &trans          &trans  &trans  &trans  &trans
&trans        &trans          &trans           &trans          &trans  &trans  &trans  &trans
&trans        &trans          &trans           &trans          &trans  &trans  &trans  &trans  &trans  &trans  &trans  &trans  &trans  &trans  &trans  &trans
&trans        &trans          &trans           &trans          &trans  &trans  &trans  &trans  &trans  &trans  &trans  &trans  &trans  &trans  &trans  &trans
            >;

            sensor-bindings = <&enc_vk 42 43>, <&enc_vk 44 45>;
        };
    };
};
